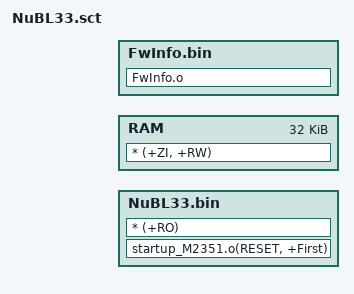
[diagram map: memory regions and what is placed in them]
#! armclang --target=arm-arm-none-eabi -march=armv8-m.base -E -xc
#define SCATTER_FILE
#include "..\..\NuBL32\partition_M2351.h"

NUBL33 FMC_NON_SECURE_BASE
{
    NuBL33.bin +0
    {
        startup_M2351.o(RESET, +First)
        * (+RO)
    }
    
    RAM NON_SECURE_SRAM_BASE 0x8000
    {
        * (+ZI, +RW)
    }
}

;NUBL33_INFO 0x10078000  ; located in 480K
NUBL33_INFO FMC_NON_SECURE_BASE+0x38000  ; located in 480K
{
    FwInfo.bin +0
    {
        FwInfo.o
    }
}
